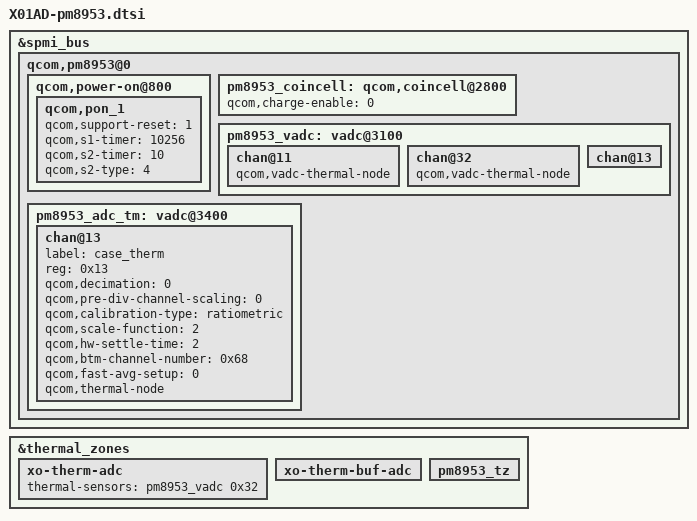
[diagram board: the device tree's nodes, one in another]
/*
 * Copyright (c) 2015-2018, The Linux Foundation. All rights reserved.
 *
 * This program is free software; you can redistribute it and/or modify
 * it under the terms of the GNU General Public License version 2 and
 * only version 2 as published by the Free Software Foundation.
 *
 * This program is distributed in the hope that it will be useful,
 * but WITHOUT ANY WARRANTY; without even the implied warranty of
 * MERCHANTABILITY or FITNESS FOR A PARTICULAR PURPOSE.  See the
 * GNU General Public License for more details.
 */

&spmi_bus {
	qcom,pm8953@0 {
		qcom,power-on@800 {
			qcom,pon_1 {
				qcom,support-reset = <1>;
				qcom,s1-timer = <10256>;
				qcom,s2-timer = <10>;
				qcom,s2-type = <4>;
			};
		};

		pm8953_coincell: qcom,coincell@2800 {
			qcom,charge-enable = <0>;
		};

		pm8953_vadc: vadc@3100 {
			chan@11 {
				qcom,vadc-thermal-node;
			};

			chan@32 {
				qcom,vadc-thermal-node;
			};

			chan@13 {
				/delete-property/ qcom,vadc-thermal-node;
			};
		};

		pm8953_adc_tm: vadc@3400 {
			/delete-node/ chan@32;

			chan@13 {
				label = "case_therm";
				reg = <0x13>;
				qcom,decimation = <0>;
				qcom,pre-div-channel-scaling = <0>;
				qcom,calibration-type = "ratiometric";
				qcom,scale-function = <2>;
				qcom,hw-settle-time = <2>;
				qcom,btm-channel-number = <0x68>;
				qcom,fast-avg-setup = <0>;
				qcom,thermal-node;
			};
		};
	};
};

&thermal_zones {
	xo-therm-adc {
		thermal-sensors = <&pm8953_vadc 0x32>;

		/delete-property/ wake-capable-sensor;
	};

	xo-therm-buf-adc {
		/delete-property/ wake-capable-sensor;
	};

	pm8953_tz {
		/delete-property/ wake-capable-sensor;
	};
};
